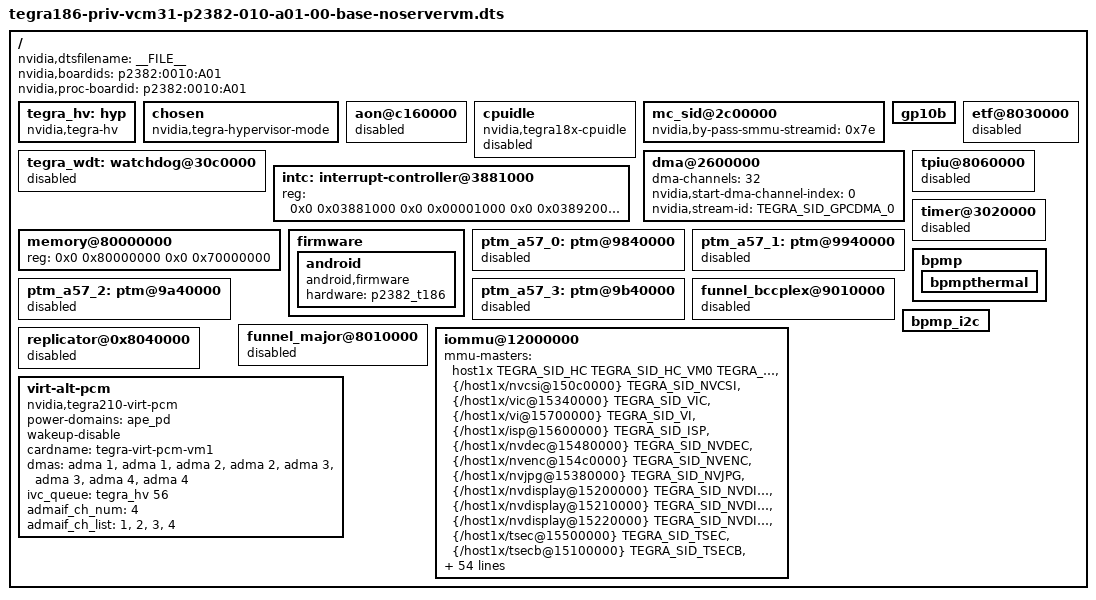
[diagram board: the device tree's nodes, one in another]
/*
 * tegra186-priv-vcm31-p2382-010-a01-00-base.dts: P2382(sunstreaker) base dts
 * file
 *
 * Copyright (c) 2016, NVIDIA CORPORATION.  All rights reserved.
 *
 * This program is free software; you can redistribute it and/or modify
 * it under the terms of the GNU General Public License as published by
 * the Free Software Foundation; version 2 of the License.
 *
 * This program is distributed in the hope that it will be useful, but WITHOUT
 * ANY WARRANTY; without even the implied warranty of MERCHANTABILITY or
 * FITNESS FOR A PARTICULAR PURPOSE.  See the GNU General Public License for
 * more details.
 */

#include "tegra186-platforms/tegra186-vcm31-p2382-common.dtsi"
#include "tegra186-platforms/tegra186-vcm31-p2382-disp.dtsi"
#include "tegra186-platforms/tegra186-vcm31-camera-ccplex.dtsi"

/ {
	nvidia,dtsfilename = __FILE__;
	nvidia,boardids = "p2382:0010:A01";
	nvidia,proc-boardid = "p2382:0010:A01";

	tegra_hv: hyp {
		compatible = "nvidia,tegra-hv";
		status = "okay";
	};

	chosen {
		nvidia,tegra-hypervisor-mode;
	};
	aon@c160000 {
		status = "disabled";
	};

	cpuidle {
		compatible = "nvidia,tegra18x-cpuidle";
		status = "disabled";
	};

	mc_sid@2c00000 {
		nvidia,by-pass-smmu-streamid = <0x7e>;
		status = "okay";
	};

	tegra_wdt:watchdog@30c0000 {
		status = "disabled";
	};

	gp10b {
			status = "okay";
	};

	dma@2600000 {
		dma-channels = <32>;
		nvidia,start-dma-channel-index = <0>;
		nvidia,stream-id = <TEGRA_SID_GPCDMA_0>;
		status = "okay";
	};

	intc: interrupt-controller@3881000 {
		reg = <0x0 0x03881000 0x0 0x00001000
		       0x0 0x03892000 0x0 0x00002000>;
	};
	memory@80000000 {
		device_type = "memory";
		reg = <0x0 0x80000000 0x0 0x70000000>;
	};

	firmware {
		android {
			compatible = "android,firmware";
			hardware = "p2382_t186";
		};
	};
	ptm_a57_0: ptm@9840000 {
		status = "disabled";
	};

	ptm_a57_1: ptm@9940000 {
		status = "disabled";
	};

	ptm_a57_2: ptm@9a40000 {
		status = "disabled";
	};

	ptm_a57_3: ptm@9b40000 {
		status = "disabled";
	};

	funnel_bccplex@9010000 {
		status = "disabled";
	};

	funnel_major@8010000 {
		status = "disabled";
	};

	replicator@0x8040000 {
		status = "disabled";
	};

	etf@8030000 {
		status = "disabled";
	};

	tpiu@8060000 {
		status = "disabled";
	};

	watchdog@30c0000 {
		status = "disabled";
	};

	timer@3020000 {
		status = "disabled";
	};

    bpmp {
        status = "okay";
        bpmpthermal {
            status = "okay";
        };
    };

    bpmp_i2c {
        status = "okay";
    };

	iommu@12000000{

		mmu-masters = <&host1x				TEGRA_SID_HC
								TEGRA_SID_HC_VM0
								TEGRA_SID_HC_VM1
								TEGRA_SID_HC_VM2
								TEGRA_SID_HC_VM3
								TEGRA_SID_HC_VM4
								TEGRA_SID_HC_VM5
								TEGRA_SID_HC_VM6
								TEGRA_SID_HC_VM7>,
			      <&{/host1x/nvcsi@150c0000}	TEGRA_SID_NVCSI>,
			      <&{/host1x/vic@15340000}		TEGRA_SID_VIC>,
			      <&{/host1x/vi@15700000}		TEGRA_SID_VI>,
			      <&{/host1x/isp@15600000}		TEGRA_SID_ISP>,
			      <&{/host1x/nvdec@15480000}	TEGRA_SID_NVDEC>,
			      <&{/host1x/nvenc@154c0000}	TEGRA_SID_NVENC>,
			      <&{/host1x/nvjpg@15380000}	TEGRA_SID_NVJPG>,
			      <&{/host1x/nvdisplay@15200000}	TEGRA_SID_NVDISPLAY>,
			      <&{/host1x/nvdisplay@15210000}	TEGRA_SID_NVDISPLAY>,
			      <&{/host1x/nvdisplay@15220000}	TEGRA_SID_NVDISPLAY>,
			      <&{/host1x/tsec@15500000}		TEGRA_SID_TSEC>,
			      <&{/host1x/tsecb@15100000}	TEGRA_SID_TSECB>,
			      <&{/host1x/se@15810000}		TEGRA_SID_SE>,
			      <&{/host1x/se@15820000}		TEGRA_SID_SE1>,
			      <&{/host1x/se@15830000}		TEGRA_SID_SE2>,
			      <&{/host1x/se@15840000}		TEGRA_SID_SE3>,
			      <&{/smmu_test}			TEGRA_SID_SMMU_TEST>,
			      <&{/gp10b}			TEGRA_SID_GPUB>,
			      <&host1x_ctx0			TEGRA_SID_HOST1X_CTX0>,
			      <&host1x_ctx1			TEGRA_SID_HOST1X_CTX1>,
			      <&host1x_ctx2			TEGRA_SID_HOST1X_CTX2>,
			      <&host1x_ctx3			TEGRA_SID_HOST1X_CTX3>,
			      <&host1x_ctx4			TEGRA_SID_HOST1X_CTX4>,
			      <&host1x_ctx5			TEGRA_SID_HOST1X_CTX5>,
			      <&host1x_ctx6			TEGRA_SID_HOST1X_CTX6>,
			      <&host1x_ctx7			TEGRA_SID_HOST1X_CTX7>,

			      /* Non-host devices. */
			      <&{/adsp@2993000}		TEGRA_SID_APE>,
			      <&{/ether_qos@2490000}	TEGRA_SID_EQOS>,
			      <&{/sdhci@3460000}	TEGRA_SID_SDMMC4A>,
			      <&{/sdhci@3440000}	TEGRA_SID_SDMMC3A>,
			      <&{/sdhci@3420000}	TEGRA_SID_SDMMC2A>,
			      <&{/sdhci@3400000}	TEGRA_SID_SDMMC1A>,
			      <&{/ufshci@2450000}	TEGRA_SID_UFSHC>,
			      <&{/xhci@3530000}		TEGRA_SID_XUSB_HOST>,
			      <&{/xudc@3550000}		TEGRA_SID_XUSB_DEV>,
			      <&{/hda@3510000}		TEGRA_SID_HDA>,
			      <&tegra_adsp_audio	TEGRA_SID_APE>,
			      <&{/sound}		TEGRA_SID_APE>,
			      <&{/sound_ref}		TEGRA_SID_APE>,
			      <&{/virt-alt-pcm}		TEGRA_SID_APE>,
			      <&{/pcie-controller@10003000} TEGRA_SID_AFI>,
			      <&{/ahci-sata@3507000}	TEGRA_SID_SATA2>,
			      <&{/aon@c160000}		TEGRA_SID_AON>,
			      <&{/rtcpu@b000000}	TEGRA_SID_SCE>,
			      <&{/bpmp}			TEGRA_SID_BPMP>,
			      <&{/dma@2600000}		TEGRA_SID_GPCDMA_0>,
			      <&{/spi@3210000}		TEGRA_SID_GPCDMA_0>,
			      <&{/spi@3230000}		TEGRA_SID_GPCDMA_0>,
			      <&{/spi@3240000}		TEGRA_SID_GPCDMA_0>,
			      <&{/spi@3270000}		TEGRA_SID_GPCDMA_0>,
			      <&{/spi@c260000}		TEGRA_SID_GPCDMA_0>,
			      <&{/serial@3100000}	TEGRA_SID_GPCDMA_0>,
			      <&{/serial@3110000}	TEGRA_SID_GPCDMA_0>,
			      <&{/serial@c280000}	TEGRA_SID_GPCDMA_0>,
			      <&{/serial@3130000}	TEGRA_SID_GPCDMA_0>,
			      <&{/serial@3140000}	TEGRA_SID_GPCDMA_0>,
			      <&{/serial@3150000}	TEGRA_SID_GPCDMA_0>,
			      <&{/serial@c290000}	TEGRA_SID_GPCDMA_0>,
			      <&{/i2c@3160000}		TEGRA_SID_GPCDMA_0>,
			      <&{/i2c@c240000}		TEGRA_SID_GPCDMA_0>,
			      <&{/i2c@3180000}		TEGRA_SID_GPCDMA_0>,
			      <&{/i2c@3190000}		TEGRA_SID_GPCDMA_0>,
			      <&{/i2c@31b0000}		TEGRA_SID_GPCDMA_0>,
			      <&{/i2c@31c0000}		TEGRA_SID_GPCDMA_0>,
			      <&{/i2c@c250000}		TEGRA_SID_GPCDMA_0>,
			      <&{/i2c@31e0000}		TEGRA_SID_GPCDMA_0>;
		};

	virt-alt-pcm {
		status = "okay";
		compatible = "nvidia,tegra210-virt-pcm";
		#stream-id-cells = <1>;
		power-domains = <&ape_pd>;
		wakeup-disable;
		cardname = "tegra-virt-pcm-vm1";
		dmas = <&adma 1>, <&adma 1>, <&adma 2>, <&adma 2>,
			<&adma 3>, <&adma 3>, <&adma 4>, <&adma 4>;
		dma-names = "rx1", "tx1", "rx2", "tx2",
			"rx3", "tx3", "rx4", "tx4";
		ivc_queue = <&tegra_hv 56>;
		admaif_ch_num = <4>;
		admaif_ch_list = <1>, <2>, <3>, <4>;
        };

    /delete-node/ axi2apb@2390000;
    /delete-node/ axi2apb@23a0000;
    /delete-node/ axi2apb@23b0000;
    /delete-node/ axi2apb@23c0000;
    /delete-node/ axi2apb@23d0000;
    /delete-node/ axip2p@2100000;
    /delete-node/ axip2p@2110000;
    /delete-node/ axip2p@2120000;
    /delete-node/ axip2p@2130000;
    /delete-node/ axip2p@2140000;
    /delete-node/ axip2p@2150000;
    /delete-node/ axip2p@2160000;
    /delete-node/ axip2p@2170000;
    /delete-node/ axip2p@2180000;
    /delete-node/ axip2p@2190000;
};
